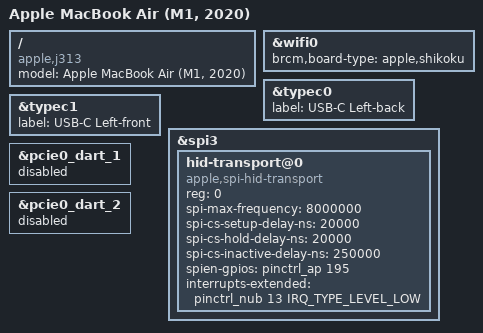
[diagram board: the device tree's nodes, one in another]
// SPDX-License-Identifier: GPL-2.0+ OR MIT
/*
 * Apple MacBook Air (M1, 2020)
 *
 * target-type: J313
 *
 * Copyright The Asahi Linux Contributors
 */

/dts-v1/;

#include "t8103.dtsi"
#include "t8103-jxxx.dtsi"

/ {
	compatible = "apple,j313", "apple,t8103", "apple,arm-platform";
	model = "Apple MacBook Air (M1, 2020)";
};

&wifi0 {
	brcm,board-type = "apple,shikoku";
};

/*
 * Provide labels for the USB type C ports.
 */

&typec0 {
	label = "USB-C Left-back";
};

&typec1 {
	label = "USB-C Left-front";
};

&spi3 {
	status = "okay";

	hid-transport@0 {
		compatible = "apple,spi-hid-transport";
		reg = <0>;
		spi-max-frequency = <8000000>;
		/*
		 * cs-setup and cs-hold delays are derived from Apple's ADT
		 * Mac OS driver meta data secify 45 us for 'cs to clock' and
		 * 'clock to cs' delays.
		 */
		spi-cs-setup-delay-ns = <20000>;
		spi-cs-hold-delay-ns = <20000>;
		spi-cs-inactive-delay-ns = <250000>;
		spien-gpios = <&pinctrl_ap 195 0>;
		interrupts-extended = <&pinctrl_nub 13 IRQ_TYPE_LEVEL_LOW>;
	};
};

/*
 * Remove unused PCIe ports and disable the associated DARTs.
 */

&pcie0_dart_1 {
	status = "disabled";
};

&pcie0_dart_2 {
	status = "disabled";
};

/delete-node/ &port01;
/delete-node/ &port02;
